AUTOSAR XML (schema 00049)
package /COM/VECTOR/CFG/WORKFLOW/SYSDESC/SYNC
  system SYSTEM: category=ECU_EXTRACT
    system mapping MAPPINGS
      data-mappings:
        sender-receiver-to-signal-mapping={data-element=COMPOSITIONTYPE.VcuRxMsg1_Sig0.VcuRxMsg1_Sig0, system-signal=VcuRxMsg1_Sig0}
        sender-receiver-to-signal-mapping={data-element=COMPOSITIONTYPE.VcuRxMsg1_Sig2.VcuRxMsg1_Sig2, system-signal=VcuRxMsg1_Sig2}
        sender-receiver-to-signal-mapping={data-element=COMPOSITIONTYPE.VcuRxMsg1_Sig1.VcuRxMsg1_Sig1, system-signal=VcuRxMsg1_Sig1}
        sender-receiver-to-signal-mapping={data-element=COMPOSITIONTYPE.VcuRxMsg2_Sig3.VcuRxMsg2_Sig3, system-signal=VcuRxMsg2_Sig3}
        sender-receiver-to-signal-mapping={data-element=COMPOSITIONTYPE.VcuRxMsg1_Sig3.VcuRxMsg1_Sig3, system-signal=VcuRxMsg1_Sig3}
        sender-receiver-to-signal-mapping={data-element=COMPOSITIONTYPE.VcuRxMsg2_Sig0.VcuRxMsg2_Sig0, system-signal=VcuRxMsg2_Sig0}
        sender-receiver-to-signal-mapping={data-element=COMPOSITIONTYPE.VcuRxMsg2_Sig2.VcuRxMsg2_Sig2, system-signal=VcuRxMsg2_Sig2}
        sender-receiver-to-signal-mapping={data-element=COMPOSITIONTYPE.VcuRxMsg2_Sig1.VcuRxMsg2_Sig1, system-signal=VcuRxMsg2_Sig1}
        sender-receiver-to-signal-mapping={data-element=COMPOSITIONTYPE.VcuTxMsg1_Sig1.VcuTxMsg1_Sig1, system-signal=VcuTxMsg1_Sig1}
        sender-receiver-to-signal-mapping={data-element=COMPOSITIONTYPE.VcuTxMsg2_Sig1.VcuTxMsg2_Sig1, system-signal=VcuTxMsg2_Sig1}
        sender-receiver-to-signal-mapping={data-element=COMPOSITIONTYPE.VcuTxMsg2_Sig2.VcuTxMsg2_Sig2, system-signal=VcuTxMsg2_Sig2}
        sender-receiver-to-signal-mapping={data-element=COMPOSITIONTYPE.VcuTxMsg1_Sig3.VcuTxMsg1_Sig3, system-signal=VcuTxMsg1_Sig3}
        sender-receiver-to-signal-mapping={data-element=COMPOSITIONTYPE.VcuTxMsg2_Sig0.VcuTxMsg2_Sig0, system-signal=VcuTxMsg2_Sig0}
        sender-receiver-to-signal-mapping={data-element=COMPOSITIONTYPE.VcuTxMsg2_Sig3.VcuTxMsg2_Sig3, system-signal=VcuTxMsg2_Sig3}
        sender-receiver-to-signal-mapping={data-element=COMPOSITIONTYPE.VcuTxMsg1_Sig2.VcuTxMsg1_Sig2, system-signal=VcuTxMsg1_Sig2}
        sender-receiver-to-signal-mapping={data-element=COMPOSITIONTYPE.VcuTxMsg1_Sig0.VcuTxMsg1_Sig0, system-signal=VcuTxMsg1_Sig0}
        sender-receiver-to-signal-mapping={data-element=COMPOSITIONTYPE.EXT1_Valid.EXT1_Valid, system-signal=EXT1_Valid}
        sender-receiver-to-signal-mapping={data-element=COMPOSITIONTYPE.EXT3_Valid.EXT3_Valid, system-signal=EXT3_Valid}
        sender-receiver-to-signal-mapping={data-element=COMPOSITIONTYPE.EXT_A_IN4.EXT_A_IN4, system-signal=EXT_A_IN4}
        sender-receiver-to-signal-mapping={data-element=COMPOSITIONTYPE.EXT2_Valid.EXT2_Valid, system-signal=EXT2_Valid}
        sender-receiver-to-signal-mapping={data-element=COMPOSITIONTYPE.EXT4_Valid.EXT4_Valid, system-signal=EXT4_Valid}
        sender-receiver-to-signal-mapping={data-element=COMPOSITIONTYPE.EXT_A_IN{1..3}.EXT_A_IN{1..3}, system-signal=EXT_A_IN{1..3}}
        sender-receiver-to-signal-mapping={data-element=COMPOSITIONTYPE.EXT10_Valid.EXT10_Valid, system-signal=EXT10_Valid}
        sender-receiver-to-signal-mapping={data-element=COMPOSITIONTYPE.EXT12_Valid.EXT12_Valid, system-signal=EXT12_Valid}
        sender-receiver-to-signal-mapping={data-element=COMPOSITIONTYPE.EXT15_Valid.EXT15_Valid, system-signal=EXT15_Valid}
        sender-receiver-to-signal-mapping={data-element=COMPOSITIONTYPE.EXT5_Valid.EXT5_Valid, system-signal=EXT5_Valid}
        sender-receiver-to-signal-mapping={data-element=COMPOSITIONTYPE.EXT_A_IN15.EXT_A_IN15, system-signal=EXT_A_IN15}
        sender-receiver-to-signal-mapping={data-element=COMPOSITIONTYPE.EXT7_Valid.EXT7_Valid, system-signal=EXT7_Valid}
        sender-receiver-to-signal-mapping={data-element=COMPOSITIONTYPE.EXT_A_IN13.EXT_A_IN13, system-signal=EXT_A_IN13}
        sender-receiver-to-signal-mapping={data-element=COMPOSITIONTYPE.EXT_A_IN5.EXT_A_IN5, system-signal=EXT_A_IN5}
        sender-receiver-to-signal-mapping={data-element=COMPOSITIONTYPE.EXT6_Valid.EXT6_Valid, system-signal=EXT6_Valid}
        sender-receiver-to-signal-mapping={data-element=COMPOSITIONTYPE.EXT_A_IN12.EXT_A_IN12, system-signal=EXT_A_IN12}
        sender-receiver-to-signal-mapping={data-element=COMPOSITIONTYPE.EXT_A_IN7.EXT_A_IN7, system-signal=EXT_A_IN7}
        sender-receiver-to-signal-mapping={data-element=COMPOSITIONTYPE.EXT13_Valid.EXT13_Valid, system-signal=EXT13_Valid}
        sender-receiver-to-signal-mapping={data-element=COMPOSITIONTYPE.EXT_A_IN9.EXT_A_IN9, system-signal=EXT_A_IN9}
        sender-receiver-to-signal-mapping={data-element=COMPOSITIONTYPE.EXT9_Valid.EXT9_Valid, system-signal=EXT9_Valid}
        sender-receiver-to-signal-mapping={data-element=COMPOSITIONTYPE.EXT8_Valid.EXT8_Valid, system-signal=EXT8_Valid}
        sender-receiver-to-signal-mapping={data-element=COMPOSITIONTYPE.EXT11_Valid.EXT11_Valid, system-signal=EXT11_Valid}
        sender-receiver-to-signal-mapping={data-element=COMPOSITIONTYPE.EXT_A_IN6.EXT_A_IN6, system-signal=EXT_A_IN6}
        sender-receiver-to-signal-mapping={data-element=COMPOSITIONTYPE.EXT16_Valid.EXT16_Valid, system-signal=EXT16_Valid}
        sender-receiver-to-signal-mapping={data-element=COMPOSITIONTYPE.EXT14_Valid.EXT14_Valid, system-signal=EXT14_Valid}
        sender-receiver-to-signal-mapping={data-element=COMPOSITIONTYPE.EXT_A_IN16.EXT_A_IN16, system-signal=EXT_A_IN16}
        sender-receiver-to-signal-mapping={data-element=COMPOSITIONTYPE.EXT_A_IN11.EXT_A_IN11, system-signal=EXT_A_IN11}
        sender-receiver-to-signal-mapping={data-element=COMPOSITIONTYPE.EXT_A_IN8.EXT_A_IN8, system-signal=EXT_A_IN8}
        sender-receiver-to-signal-mapping={data-element=COMPOSITIONTYPE.EXT_A_IN14.EXT_A_IN14, system-signal=EXT_A_IN14}
        sender-receiver-to-signal-mapping={data-element=COMPOSITIONTYPE.EXT_A_IN10.EXT_A_IN10, system-signal=EXT_A_IN10}
        sender-receiver-to-signal-mapping={data-element=COMPOSITIONTYPE.ECC_PMP2_SpdSet.ECC_PMP2_SpdSet, system-signal=ECC_PMP2_SpdSet}
        sender-receiver-to-signal-mapping={data-element=COMPOSITIONTYPE.ECC_PMP3_SpdSet.ECC_PMP3_SpdSet, system-signal=ECC_PMP3_SpdSet}
        sender-receiver-to-signal-group-mapping={data-element=COMPOSITIONTYPE.SG_IBS_Status_06_Signal_Group.SG_IBS_Status_06_Signal_Group, signal-group=SG_IBS_Status_06_Signal_Group, type-mapping=sender-rec-record-type-mapping=record-element-mappings=[{implementation-record-element=IBS_HDCSts, system-signal=IBS_HDCSts}, {implementation-record-element=IBS_TireWarnFrntRi, system-signal=IBS_TireWarnFrntRi}, {implementation-record-element=IBS_RollerbenchMode, system-signal=IBS_RollerbenchMode}, {implementation-record-element=IBS_TireWarnReLe, system-signal=IBS_TireWarnReLe}, {implementation-record-element=IBS_TPMS_ResetSts, system-signal=IBS_TPMS_ResetSts}, {implementation-record-element=IBS_AVHSts, system-signal=IBS_AVHSts}, {implementation-record-element=IBS_TireWarnFrntLe, system-signal=IBS_TireWarnFrntLe}, {implementation-record-element=Checksum_0BC, system-signal=Checksum_0BC}, {implementation-record-element=IBS_TireWarnReRi, system-signal=IBS_TireWarnReRi}, {implementation-record-element=MessageCounter_0BC, system-signal=MessageCounter_0BC}, {implementation-record-element=IBS_HBAActive, system-signal=IBS_HBAActive}, {implementation-record-element=IBS_EPBFailureStatus, system-signal=IBS_EPBFailureStatus}, {implementation-record-element=IBS_TireMonSysSts, system-signal=IBS_TireMonSysSts}, {implementation-record-element=IBS_RWUAvailable, system-signal=IBS_RWUAvailable}, {implementation-record-element=IBS_RWUActive, system-signal=IBS_RWUActive}, {implementation-record-element=IBS_FactoryMode, system-signal=IBS_FactoryMode}, {implementation-record-element=IBS_ESCOffSts, system-signal=IBS_ESCOffSts}, {implementation-record-element=IBS_BrakeFluidWarning, system-signal=IBS_BrakeFluidWarning}, {implementation-record-element=IBS_ESClampdisplay, system-signal=IBS_ESClampdisplay}, {implementation-record-element=IBS_MaintenaceMode, system-signal=IBS_MaintenaceMode}]}
        sender-receiver-to-signal-group-mapping={data-element=COMPOSITIONTYPE.SG_VCU_BMS_Signal_Group.SG_VCU_BMS_Signal_Group, signal-group=SG_VCU_BMS_Signal_Group, type-mapping=sender-rec-record-type-mapping=record-element-mappings=[{implementation-record-element=VCU_ActDriveMode, system-signal=VCU_ActDriveMode}, {implementation-record-element=VCU_RequestedModeBMS, system-signal=VCU_RequestedModeBMS}, {implementation-record-element=VCU_BMSTargetThermLevel, system-signal=VCU_BMSTargetThermLevel}, {implementation-record-element=MessageCounter_0D1, system-signal=MessageCounter_0D1}, {implementation-record-element=VCU_DrvModSwitchWarn, system-signal=VCU_DrvModSwitchWarn}, {implementation-record-element=VCU_HVStatus, system-signal=VCU_HVStatus}, {implementation-record-element=VCU_ActiveEnergyProfile, system-signal=VCU_ActiveEnergyProfile}, {implementation-record-element=VCU_ActiveRgnBrkProfile, system-signal=VCU_ActiveRgnBrkProfile}, {implementation-record-element=VCU_RegenBrakeLightRequest, system-signal=VCU_RegenBrakeLightRequest}, {implementation-record-element=Checksum_0D1, system-signal=Checksum_0D1}, {implementation-record-element=VCU_RegenBrakeLightReqVld, system-signal=VCU_RegenBrakeLightReqVld}, {implementation-record-element=VCU_IsomeasurmentSwitch, system-signal=VCU_IsomeasurmentSwitch}, {implementation-record-element=VCU_Chargestatus, system-signal=VCU_Chargestatus}, {implementation-record-element=VCU_BMS_Control_of_NegRelay, system-signal=VCU_BMS_Control_of_NegRelay}, {implementation-record-element=VCU_LimitLevel, system-signal=VCU_LimitLevel}]}
    root-software-compositions:
      root sw composition prototype COMPOSITIONTYPE: flat-map=FLATMAP, software-composition=COMPOSITIONTYPE
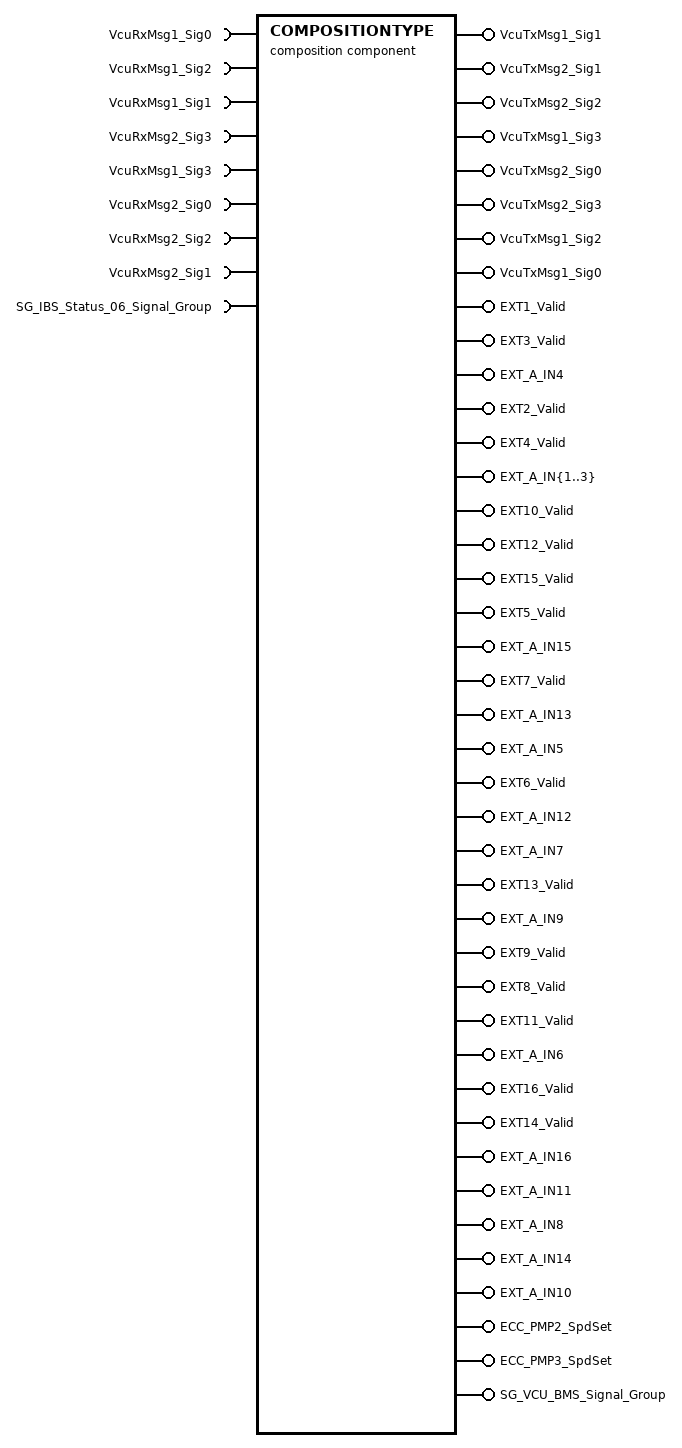
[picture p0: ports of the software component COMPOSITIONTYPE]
  composition sw component type COMPOSITIONTYPE  # UB:Derived from original system description
    8 x require port:
      VcuRxMsg1_Sig0: nonqueued-receiver-com-spec{data-element=VcuRxMsg1_Sig0, init-value=0}, required-interface=VcuRxMsg1_Sig0
      VcuRxMsg1_Sig2: nonqueued-receiver-com-spec{data-element=VcuRxMsg1_Sig2, init-value=0}, required-interface=VcuRxMsg1_Sig2
      VcuRxMsg1_Sig1: nonqueued-receiver-com-spec{data-element=VcuRxMsg1_Sig1, init-value=0}, required-interface=VcuRxMsg1_Sig1
      VcuRxMsg2_Sig3: nonqueued-receiver-com-spec{data-element=VcuRxMsg2_Sig3, init-value=0}, required-interface=VcuRxMsg2_Sig3
      VcuRxMsg1_Sig3: nonqueued-receiver-com-spec{data-element=VcuRxMsg1_Sig3, init-value=0}, required-interface=VcuRxMsg1_Sig3
      VcuRxMsg2_Sig0: nonqueued-receiver-com-spec{data-element=VcuRxMsg2_Sig0, init-value=0}, required-interface=VcuRxMsg2_Sig0
      VcuRxMsg2_Sig2: nonqueued-receiver-com-spec{data-element=VcuRxMsg2_Sig2, init-value=0}, required-interface=VcuRxMsg2_Sig2
      VcuRxMsg2_Sig1: nonqueued-receiver-com-spec{data-element=VcuRxMsg2_Sig1, init-value=0}, required-interface=VcuRxMsg2_Sig1
    42 x provide port:
      VcuTxMsg1_Sig1: nonqueued-sender-com-spec{data-element=VcuTxMsg1_Sig1, init-value=0}, provided-interface=VcuTxMsg1_Sig1
      VcuTxMsg2_Sig1: nonqueued-sender-com-spec{data-element=VcuTxMsg2_Sig1, init-value=0}, provided-interface=VcuTxMsg2_Sig1
      VcuTxMsg2_Sig2: nonqueued-sender-com-spec{data-element=VcuTxMsg2_Sig2, init-value=0}, provided-interface=VcuTxMsg2_Sig2
      VcuTxMsg1_Sig3: nonqueued-sender-com-spec{data-element=VcuTxMsg1_Sig3, init-value=0}, provided-interface=VcuTxMsg1_Sig3
      VcuTxMsg2_Sig0: nonqueued-sender-com-spec{data-element=VcuTxMsg2_Sig0, init-value=0}, provided-interface=VcuTxMsg2_Sig0
      VcuTxMsg2_Sig3: nonqueued-sender-com-spec{data-element=VcuTxMsg2_Sig3, init-value=0}, provided-interface=VcuTxMsg2_Sig3
      VcuTxMsg1_Sig2: nonqueued-sender-com-spec{data-element=VcuTxMsg1_Sig2, init-value=0}, provided-interface=VcuTxMsg1_Sig2
      VcuTxMsg1_Sig0: nonqueued-sender-com-spec{data-element=VcuTxMsg1_Sig0, init-value=0}, provided-interface=VcuTxMsg1_Sig0
      EXT1_Valid: nonqueued-sender-com-spec{data-element=EXT1_Valid, init-value=0}, provided-interface=EXT1_Valid
      EXT3_Valid: nonqueued-sender-com-spec{data-element=EXT3_Valid, init-value=0}, provided-interface=EXT3_Valid
      EXT_A_IN4: nonqueued-sender-com-spec{data-element=EXT_A_IN4, init-value=0}, provided-interface=EXT_A_IN4
      EXT2_Valid: nonqueued-sender-com-spec{data-element=EXT2_Valid, init-value=0}, provided-interface=EXT2_Valid
      EXT4_Valid: nonqueued-sender-com-spec{data-element=EXT4_Valid, init-value=0}, provided-interface=EXT4_Valid
      EXT_A_IN{1..3}: nonqueued-sender-com-spec{data-element=EXT_A_IN{1..3}, init-value=0}, provided-interface=EXT_A_IN{1..3}
      EXT10_Valid: nonqueued-sender-com-spec{data-element=EXT10_Valid, init-value=0}, provided-interface=EXT10_Valid
      EXT12_Valid: nonqueued-sender-com-spec{data-element=EXT12_Valid, init-value=0}, provided-interface=EXT12_Valid
      EXT15_Valid: nonqueued-sender-com-spec{data-element=EXT15_Valid, init-value=0}, provided-interface=EXT15_Valid
      EXT5_Valid: nonqueued-sender-com-spec{data-element=EXT5_Valid, init-value=0}, provided-interface=EXT5_Valid
      EXT_A_IN15: nonqueued-sender-com-spec{data-element=EXT_A_IN15, init-value=0}, provided-interface=EXT_A_IN15
      EXT7_Valid: nonqueued-sender-com-spec{data-element=EXT7_Valid, init-value=0}, provided-interface=EXT7_Valid
      EXT_A_IN13: nonqueued-sender-com-spec{data-element=EXT_A_IN13, init-value=0}, provided-interface=EXT_A_IN13
      EXT_A_IN5: nonqueued-sender-com-spec{data-element=EXT_A_IN5, init-value=0}, provided-interface=EXT_A_IN5
      EXT6_Valid: nonqueued-sender-com-spec{data-element=EXT6_Valid, init-value=0}, provided-interface=EXT6_Valid
      EXT_A_IN12: nonqueued-sender-com-spec{data-element=EXT_A_IN12, init-value=0}, provided-interface=EXT_A_IN12
      EXT_A_IN7: nonqueued-sender-com-spec{data-element=EXT_A_IN7, init-value=0}, provided-interface=EXT_A_IN7
      EXT13_Valid: nonqueued-sender-com-spec{data-element=EXT13_Valid, init-value=0}, provided-interface=EXT13_Valid
      EXT_A_IN9: nonqueued-sender-com-spec{data-element=EXT_A_IN9, init-value=0}, provided-interface=EXT_A_IN9
      EXT9_Valid: nonqueued-sender-com-spec{data-element=EXT9_Valid, init-value=0}, provided-interface=EXT9_Valid
      EXT8_Valid: nonqueued-sender-com-spec{data-element=EXT8_Valid, init-value=0}, provided-interface=EXT8_Valid
      EXT11_Valid: nonqueued-sender-com-spec{data-element=EXT11_Valid, init-value=0}, provided-interface=EXT11_Valid
      EXT_A_IN6: nonqueued-sender-com-spec{data-element=EXT_A_IN6, init-value=0}, provided-interface=EXT_A_IN6
      EXT16_Valid: nonqueued-sender-com-spec{data-element=EXT16_Valid, init-value=0}, provided-interface=EXT16_Valid
      EXT14_Valid: nonqueued-sender-com-spec{data-element=EXT14_Valid, init-value=0}, provided-interface=EXT14_Valid
      EXT_A_IN16: nonqueued-sender-com-spec{data-element=EXT_A_IN16, init-value=0}, provided-interface=EXT_A_IN16
      EXT_A_IN11: nonqueued-sender-com-spec{data-element=EXT_A_IN11, init-value=0}, provided-interface=EXT_A_IN11
      EXT_A_IN8: nonqueued-sender-com-spec{data-element=EXT_A_IN8, init-value=0}, provided-interface=EXT_A_IN8
      EXT_A_IN14: nonqueued-sender-com-spec{data-element=EXT_A_IN14, init-value=0}, provided-interface=EXT_A_IN14
      EXT_A_IN10: nonqueued-sender-com-spec{data-element=EXT_A_IN10, init-value=0}, provided-interface=EXT_A_IN10
      ECC_PMP2_SpdSet: nonqueued-sender-com-spec{data-element=ECC_PMP2_SpdSet, init-value=0}, provided-interface=ECC_PMP2_SpdSet
      ECC_PMP3_SpdSet: nonqueued-sender-com-spec{data-element=ECC_PMP3_SpdSet, init-value=0}, provided-interface=ECC_PMP3_SpdSet
    require port SG_IBS_Status_06_Signal_Group: nonqueued-receiver-com-spec{data-element=SG_IBS_Status_06_Signal_Group, uses-end-to-end-protection=true, enable-update=true, init-value=fields=[Checksum_0BC:0, IBS_AVHSts:0, IBS_BrakeFluidWarning:0, IBS_EPBFailureStatus:0, IBS_ESClampdisplay:0, IBS_ESCOffSts:0, IBS_FactoryMode:0, IBS_HBAActive:0, IBS_HDCSts:0, IBS_MaintenaceMode:0, IBS_RollerbenchMode:0, IBS_RWUActive:0, IBS_RWUAvailable:0, IBS_TireMonSysSts:0, IBS_TireWarnFrntLe:0, IBS_TireWarnFrntRi:0, IBS_TireWarnReLe:0, IBS_TireWarnReRi:0, IBS_TPMS_ResetSts:0, MessageCounter_0BC:0]}, required-interface=SG_IBS_Status_06_Signal_Group
    provide port SG_VCU_BMS_Signal_Group: nonqueued-sender-com-spec{data-element=SG_VCU_BMS_Signal_Group, uses-end-to-end-protection=true, init-value=fields=[Checksum_0D1:0, MessageCounter_0D1:0, VCU_ActDriveMode:0, VCU_ActiveEnergyProfile:0, VCU_ActiveRgnBrkProfile:0, VCU_BMS_Control_of_NegRelay:0, VCU_BMSTargetThermLevel:0, VCU_Chargestatus:0, VCU_DrvModSwitchWarn:0, VCU_HVStatus:0, VCU_IsomeasurmentSwitch:0, VCU_LimitLevel:0, VCU_RegenBrakeLightRequest:0, VCU_RegenBrakeLightReqVld:0, VCU_RequestedModeBMS:0]}, provided-interface=SG_VCU_BMS_Signal_Group
    19 x component:
      BswM: type=BswM
      EcuM: type=EcuM
      Os_OsCore0_swc: type=Os_OsCore0_swc
      SWC1: type=SWC1
      ComM: type=ComM
      Det: type=Det
      PowerMng_SWC: type=PowerMng_SWC
      Com_SWC: type=Com_SWC
      NvM: type=NvM
      NvM_SWC: type=NvM_SWC
      DemMaster_0: type=DemMaster_0
      DemSatellite_0: type=DemSatellite_0
      Dcm: type=Dcm
      DIAG_SWC: type=DIAG_SWC
      IoHwAb_SWC: type=IoHwAb_SWC
      Os_OsCore1_swc: type=Os_OsCore1_swc
      Os_OsCore2_swc: type=Os_OsCore2_swc
      Core2App_SWC: type=Core2App_SWC
      Core1App_SWC: type=Core1App_SWC
    connect BswM.Switch_ESH_ModeSwitch -> BswM.Notification_ESH_ModeNotification
    connect SWC1.Request_ESH_RunRequest_0 -> BswM.Request_ESH_RunRequest_0
    connect ComM.UR_CN_TC37X_VCU_CAN00_b1b4f272 -> SWC1.UR_CN_TC37X_VCU_CAN00_b1b4f272
    delegate Com_SWC.VcuRxMsg1_Sig0 <-> outer port VcuRxMsg1_Sig0  # UB:Derived from original system description
    delegate Com_SWC.VcuRxMsg1_Sig2 <-> outer port VcuRxMsg1_Sig2  # UB:Derived from original system description
    delegate Com_SWC.VcuRxMsg1_Sig1 <-> outer port VcuRxMsg1_Sig1  # UB:Derived from original system description
    delegate Com_SWC.VcuRxMsg2_Sig3 <-> outer port VcuRxMsg2_Sig3  # UB:Derived from original system description
    delegate Com_SWC.VcuRxMsg1_Sig3 <-> outer port VcuRxMsg1_Sig3  # UB:Derived from original system description
    delegate Com_SWC.VcuRxMsg2_Sig0 <-> outer port VcuRxMsg2_Sig0  # UB:Derived from original system description
    delegate Com_SWC.VcuRxMsg2_Sig2 <-> outer port VcuRxMsg2_Sig2  # UB:Derived from original system description
    delegate Com_SWC.VcuRxMsg2_Sig1 <-> outer port VcuRxMsg2_Sig1  # UB:Derived from original system description
    delegate Com_SWC.VcuTxMsg1_Sig1 <-> outer port VcuTxMsg1_Sig1  # UB:Derived from original system description
    delegate Com_SWC.VcuTxMsg2_Sig1 <-> outer port VcuTxMsg2_Sig1  # UB:Derived from original system description
    delegate Com_SWC.VcuTxMsg2_Sig2 <-> outer port VcuTxMsg2_Sig2  # UB:Derived from original system description
    delegate Com_SWC.VcuTxMsg1_Sig3 <-> outer port VcuTxMsg1_Sig3  # UB:Derived from original system description
    delegate Com_SWC.VcuTxMsg2_Sig0 <-> outer port VcuTxMsg2_Sig0  # UB:Derived from original system description
    delegate Com_SWC.VcuTxMsg2_Sig3 <-> outer port VcuTxMsg2_Sig3  # UB:Derived from original system description
    delegate Com_SWC.VcuTxMsg1_Sig2 <-> outer port VcuTxMsg1_Sig2  # UB:Derived from original system description
    delegate Com_SWC.VcuTxMsg1_Sig0 <-> outer port VcuTxMsg1_Sig0  # UB:Derived from original system description
    connect SWC1.NvM_Data_IF_UserData1_Send -> NvM_SWC.NvM_Data_IF_UserData1_Recv  # UB:Derived from original system description
    connect NvM_SWC.NvM_Data_IF_UserData1_Send -> SWC1.NvM_Data_IF_UserData1_Recv  # UB:Derived from original system description
    connect SWC1.NvSWC_NvMNotifyJobFinished_UserData1 -> NvM_SWC.NvSWC_NvMNotifyJobFinished_NVBlockDescriptor_UserData1  # UB:Derived from original system description
    connect SWC1.NvM_Data_IF_UserData2_Send -> NvM_SWC.NvM_Data_IF_UserData2_Rcev  # UB:Derived from original system description
    connect NvM_SWC.NvM_Data_IF_UserData2_Send -> SWC1.NvM_Data_IF_UserData2_Recv  # UB:Derived from original system description
    connect SWC1.NvSWC_NvMNotifyJobFinished_UserData2 -> NvM_SWC.NvSWC_NvMNotifyJobFinished_NVBlockDescriptor_UserData2  # UB:Derived from original system description
    connect NvM.PS_SWC1NvBlockNeed_UserData3 -> SWC1.NvMService_AC3_SRBS_NvBlockNeed_UserData3
    connect NvM_SWC.NvMService_NVBlockDescriptor_UserData2 -> SWC1.NvSWC_UserData2_NvMService_AC3_SRBS  # UB:Derived from original system description
    connect DIAG_SWC.DataServices_VCU_DID_00_DataRecord -> Dcm.DataServices_VCU_DID_00_DataRecord
    connect NvM.PS_DIAG_SWC_NvBlockNeed_DiagDID_00 -> DIAG_SWC.PS_DIAG_SWC_NvBlockNeed_DiagDID_00
    connect DIAG_SWC.RoutineServices_Vcu_Roution_00 -> Dcm.RoutineServices_Vcu_Roution_00
    connect ComM.UR_CN_TC37X_VCU_CAN01_5e76994c -> SWC1.UR_CN_TC37X_VCU_CAN01_5e76994c
    delegate Com_SWC.EXT1_Valid <-> outer port EXT1_Valid  # UB:Derived from original system description
    delegate Com_SWC.EXT3_Valid <-> outer port EXT3_Valid  # UB:Derived from original system description
    delegate Com_SWC.EXT_A_IN4 <-> outer port EXT_A_IN4  # UB:Derived from original system description
    delegate Com_SWC.EXT2_Valid <-> outer port EXT2_Valid  # UB:Derived from original system description
    delegate Com_SWC.EXT4_Valid <-> outer port EXT4_Valid  # UB:Derived from original system description
    delegate Com_SWC.EXT_A_IN{1..3} <-> outer port EXT_A_IN{1..3}  # UB:Derived from original system description
    delegate Com_SWC.EXT10_Valid <-> outer port EXT10_Valid  # UB:Derived from original system description
    delegate Com_SWC.EXT12_Valid <-> outer port EXT12_Valid  # UB:Derived from original system description
    delegate Com_SWC.EXT15_Valid <-> outer port EXT15_Valid  # UB:Derived from original system description
    delegate Com_SWC.EXT5_Valid <-> outer port EXT5_Valid  # UB:Derived from original system description
    delegate Com_SWC.EXT_A_IN15 <-> outer port EXT_A_IN15  # UB:Derived from original system description
    delegate Com_SWC.EXT7_Valid <-> outer port EXT7_Valid  # UB:Derived from original system description
    delegate Com_SWC.EXT_A_IN13 <-> outer port EXT_A_IN13  # UB:Derived from original system description
    delegate Com_SWC.EXT_A_IN5 <-> outer port EXT_A_IN5  # UB:Derived from original system description
    delegate Com_SWC.EXT6_Valid <-> outer port EXT6_Valid  # UB:Derived from original system description
    delegate Com_SWC.EXT_A_IN12 <-> outer port EXT_A_IN12  # UB:Derived from original system description
    delegate Com_SWC.EXT_A_IN7 <-> outer port EXT_A_IN7  # UB:Derived from original system description
    delegate Com_SWC.EXT13_Valid <-> outer port EXT13_Valid  # UB:Derived from original system description
    delegate Com_SWC.EXT_A_IN9 <-> outer port EXT_A_IN9  # UB:Derived from original system description
    delegate Com_SWC.EXT9_Valid <-> outer port EXT9_Valid  # UB:Derived from original system description
    delegate Com_SWC.EXT8_Valid <-> outer port EXT8_Valid  # UB:Derived from original system description
    delegate Com_SWC.EXT11_Valid <-> outer port EXT11_Valid  # UB:Derived from original system description
    delegate Com_SWC.EXT_A_IN6 <-> outer port EXT_A_IN6  # UB:Derived from original system description
    delegate Com_SWC.EXT16_Valid <-> outer port EXT16_Valid  # UB:Derived from original system description
    delegate Com_SWC.EXT14_Valid <-> outer port EXT14_Valid  # UB:Derived from original system description
    delegate Com_SWC.EXT_A_IN16 <-> outer port EXT_A_IN16  # UB:Derived from original system description
    delegate Com_SWC.EXT_A_IN11 <-> outer port EXT_A_IN11  # UB:Derived from original system description
    delegate Com_SWC.EXT_A_IN8 <-> outer port EXT_A_IN8  # UB:Derived from original system description
    delegate Com_SWC.EXT_A_IN14 <-> outer port EXT_A_IN14  # UB:Derived from original system description
    delegate Com_SWC.EXT_A_IN10 <-> outer port EXT_A_IN10  # UB:Derived from original system description
    connect ComM.UR_CN_KAMA_FP_EPT_0303_b67fd6a6 -> SWC1.UR_CN_KAMA_FP_EPT_0303_b67fd6a6
    connect ComM.UR_CN_LIN00_984dfd9e -> SWC1.UR_CN_LIN00_984dfd9e
    connect DemMaster_0.OpCycle_PowerCycle -> DIAG_SWC.OpCycle_PowerCycle
    delegate Com_SWC.ECC_PMP2_SpdSet <-> outer port ECC_PMP2_SpdSet  # UB:Derived from original system description
    delegate Com_SWC.ECC_PMP3_SpdSet <-> outer port ECC_PMP3_SpdSet  # UB:Derived from original system description
    connect DIAG_SWC.SecurityAccess_Level_3 -> Dcm.SecurityAccess_Level_3
    connect NvM.PS_DIAG_SWC_NvBlockNeed_AttemptCounter -> DIAG_SWC.NvMService_AC3_SRBS_NvBlockNeed_AttemptCounter
    connect DemSatellite_0.Event_DTC_0X000002 -> DIAG_SWC.Event_DTC_0x000002
    connect DemSatellite_0.Event_DTC_0X000003 -> DIAG_SWC.Event_DTC_0x000003
    connect DIAG_SWC.CBReadData_DID_0xf1a{0..3}_F1A{0..3}_Data -> DemMaster_0.CBReadData_DID_0xf1a{0..3}_F1A{0..3}_Data
    connect ComM.UR_CN_TC37X_VCU_CAN03_5a834971 -> SWC1.UR_CN_TC37X_VCU_CAN03_5a834971
    connect DemSatellite_0.EvtInfo_CAN01_ComLost -> DIAG_SWC.EvtInfo_CAN01_ComLost
    connect DemSatellite_0.Event_CAN01_ComLost -> DIAG_SWC.Event_CAN01_ComLost
    connect DemMaster_0.OpCycle_IgnitionCycle -> DIAG_SWC.OpCycle_IgnitionCycle
    connect DemMaster_0.EnableCond_KL15_High -> DIAG_SWC.EnableCond_KL15_High
    connect NvM.PS_DIAG_SWC_NvBlockNeed_DID_F193 -> DIAG_SWC.PS_DIAG_SWC_NvBlockNeed_DID_F193
    connect DIAG_SWC.DataServices_Hardware_Version_Hardware_Version_Number -> Dcm.DataServices_Hardware_Version_Hardware_Version_Number
    connect IoHwAb_SWC.P_Arry8Bytes -> Core1App_SWC.P_Arry8Bytes  # UB:Derived from original system description
    delegate Com_SWC.SG_IBS_Status_06_Signal_Group <-> outer port SG_IBS_Status_06_Signal_Group  # UB:Derived from original system description
    delegate Com_SWC.SG_VCU_BMS_Signal_Group <-> outer port SG_VCU_BMS_Signal_Group  # UB:Derived from original system description
    connect EcuM.EcuM_ShutdownTarget -> DIAG_SWC.EcuM_ShutdownTarget
    connect Dcm.DcmEcuReset -> DIAG_SWC.DcmEcuReset
  end to end protection set E2EPROTECTIONSET
    end to end protection ECU_Composition_SG_IBS_Status_06_Signal_Group_SG_IBS_Status_06_Signal_Group_delegated: end-to-end-profile={category=PROFILE_01, data-ids=188, data-id-mode=0, data-length=64, max-delta-counter-init=1, crc-offset=0, counter-offset=8, max-no-new-or-repeated-data=14, sync-counter-init=1, data-id-nibble-offset=0}, end-to-end-protection-variable-prototype=receiver=Com_SWC.COMPOSITIONTYPE.SG_IBS_Status_06_Signal_Group.SG_IBS_Status_06_Signal_Group
    end to end protection ECU_Composition_SG_VCU_BMS_Signal_Group_SG_VCU_BMS_Signal_Group_delegated: end-to-end-profile={category=PROFILE_01, data-ids=209, data-id-mode=0, data-length=64, max-delta-counter-init=1, crc-offset=0, counter-offset=8, max-no-new-or-repeated-data=14, sync-counter-init=1, data-id-nibble-offset=0}, end-to-end-protection-variable-prototype=Com_SWC.COMPOSITIONTYPE.SG_VCU_BMS_Signal_Group.SG_VCU_BMS_Signal_Group
  port interface mapping set PORTINTERFACEMAPPINGSET
